# Star_MC1 register map
Vendor: Arm Ltd.; Series: ARMv8-M Mainline; File version: 1.0.0
CPU: other r0p0, little endian, MPU, FPU, double-precision FPU, DSP, 8 interrupt priority bits
Registers are 32-bit, read-write, reset 0x0 unless marked. A register's access mark holds for its fields unless they carry their own. Offsets are from the block's base; [hi:lo] are bit positions; {n}, {i} and the like mark numbered series; 'fields as' and 'values as' point back to an identical list.

## BPU — Breakpoint Unit (Flash Patch and Breakpoint unit FPBv2 on STAR-MC1): up to eight hardware instruction breakpoint comparators.
Base 0xE0002000
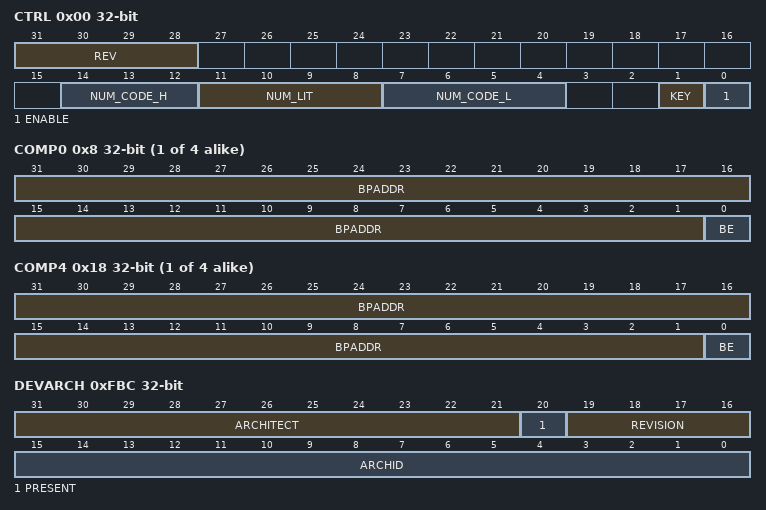
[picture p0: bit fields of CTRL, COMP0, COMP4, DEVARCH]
0x00 CTRL — Breakpoint Control Register: enable and the number of comparators. Writes must set KEY.
  [31:28] REV — FPB architecture revision: 1 = FPBv2.
  [14:12] NUM_CODE_H — Number of instruction address comparators, bits [6:4].
  [11:8] NUM_LIT — Number of literal comparators.
  [7:4] NUM_CODE_L — Number of instruction address comparators, bits [3:0].
  [1] KEY — Write 1 to enable writes to this register; reads as 0.
  [0] ENABLE — Breakpoint unit enable.
{0x8+4i} COMP{i} (i=0..3) — Comparator Register {i}
  [31:1] BPADDR — Instruction address bits [31:1] to break on.
  [0] BE — Breakpoint enable.
{0x8+4i} COMP{i} (i=4..7) — Comparator Register 0
  fields as COMP0
0xFBC DEVARCH ro — Device Architecture Register: CoreSight ARCHID of the FPB (0x1A03).
  [31:21] ARCHITECT — JEP106 code of the architect (Arm: 0x23B).
  [20] PRESENT — 1 = DEVARCH is present and its contents are valid.
  [19:16] REVISION — Architecture revision.
  [15:0] ARCHID — Architecture ID, including the architecture part number [11:0] and revision [15:12].
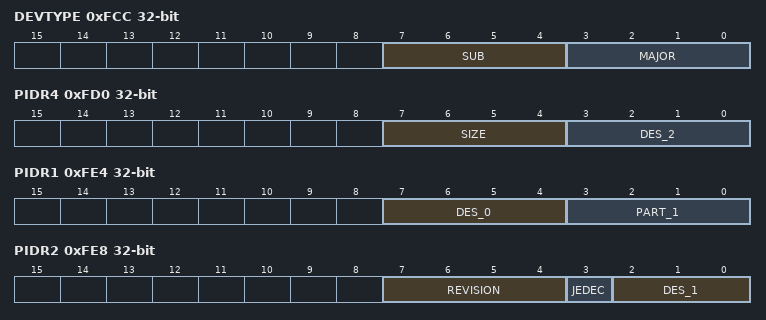
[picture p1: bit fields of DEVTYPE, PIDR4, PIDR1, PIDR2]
0xFCC DEVTYPE ro — Device Type Register: 0x00.
  [7:4] SUB — Sub type within the major class.
  [3:0] MAJOR — Major type: 0 miscellaneous, 1 trace sink, 2 trace link, 3 trace source, 4 debug control, 5 debug logic, 6 PMU.
0xFD0 PIDR4 ro — Peripheral Identification Register 4: JEP106 continuation code and component size.
  [7:4] SIZE — Log2 of the number of 4 KB blocks the component occupies (0 = one block).
  [3:0] DES_2 — JEP106 continuation code of the designer (Arm: 0x4).
{0xFC0+4i} PIDR{i} ro (i=5..7) — Peripheral Identification Register {i} (reserved, reads as zero).
0xFE0 PIDR0 ro — Peripheral Identification Register 0: part number bits [7:0].
  [7:0] PART_0 — Part number bits [7:0].
0xFE4 PIDR1 ro — Peripheral Identification Register 1: part number bits [11:8] and designer bits [3:0].
  [7:4] DES_0 — JEP106 identity code bits [3:0] of the designer.
  [3:0] PART_1 — Part number bits [11:8].
0xFE8 PIDR2 ro — Peripheral Identification Register 2: designer bits [6:4], JEDEC flag and revision.
  [7:4] REVISION — Component major revision.
  [3] JEDEC — Always 1: the designer ID is a JEDEC JEP106 code.
  [2:0] DES_1 — JEP106 identity code bits [6:4] of the designer.
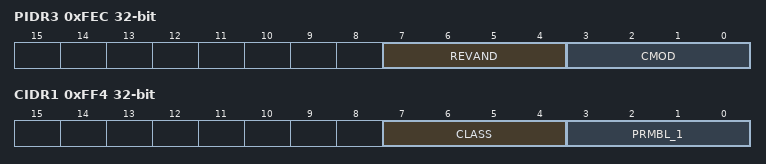
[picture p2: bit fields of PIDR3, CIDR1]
0xFEC PIDR3 ro — Peripheral Identification Register 3: customer modified and minor revision.
  [7:4] REVAND — Minor revision (metal fix) number.
  [3:0] CMOD — Customer Modified: 0 if the component has not been modified by the integrator.
0xFF0 CIDR0 ro — Component Identification Register 0: preamble byte 0 (0x0D).
  [7:0] PRMBL_0 — Preamble, reads as 0x0D.
0xFF4 CIDR1 ro — Component Identification Register 1: component class and preamble.
  [7:4] CLASS — Component class: 0x1 ROM table, 0x9 CoreSight component, 0xE generic IP, 0xF CoreLink/PrimeCell.
  [3:0] PRMBL_1 — Preamble, reads as 0x0.
0xFF8 CIDR2 ro — Component Identification Register 2: preamble byte 2 (0x05).
  [7:0] PRMBL_2 — Preamble, reads as 0x05.
0xFFC CIDR3 ro — Component Identification Register 3: preamble byte 3 (0xB1).
  [7:0] PRMBL_3 — Preamble, reads as 0xB1.

## SCnSCB — System control registers not in the SCB: the interrupt controller type and the implementation-defined Auxiliary Control Register.
Base 0xE000E000
Same registers: SCnSCB_NS 0xE002E000
0x04 ICTR ro — Interrupt Controller Type Register: how many interrupt lines the NVIC supports, in groups of 32. Read-only.
  [3:0] INTLINESNUM — Number of interrupt lines in groups of 32: the NVIC supports up to 32 x (INTLINESNUM+1) interrupts (0 = 1-32, 1 = 33-64, ...).
0x08 ACTLR — Auxiliary Control Register: implementation-defined controls that disable individual performance features (write buffering, instruction folding, interruptible multi-cycle instructions, FPU behaviours). Usually left at reset; DISDEFWBUF is useful to make imprecise BusFaults precise while debugging.
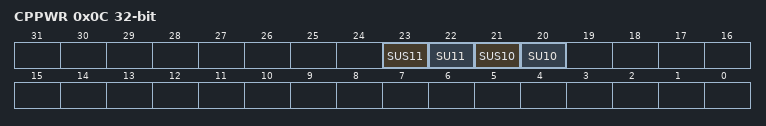
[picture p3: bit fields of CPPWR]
0x0C CPPWR — Coprocessor Power Control Register (ARMv8-M): per-coprocessor 'state unknown' permissions that let the implementation power-gate the FPU/MVE and custom coprocessors.
  [23] SUS11 — SU11 Secure only.
  [22] SU11 — State Unknown for CP11 (FPU/MVE), must equal SU10.
  [21] SUS10 — SU10 Secure only: 1 = SU10 can only be changed from Secure state.
  [20] SU10 — State Unknown for CP10 (FPU/MVE): 1 = the implementation may power down the unit and its register state may become unknown; software must then re-initialise it.
